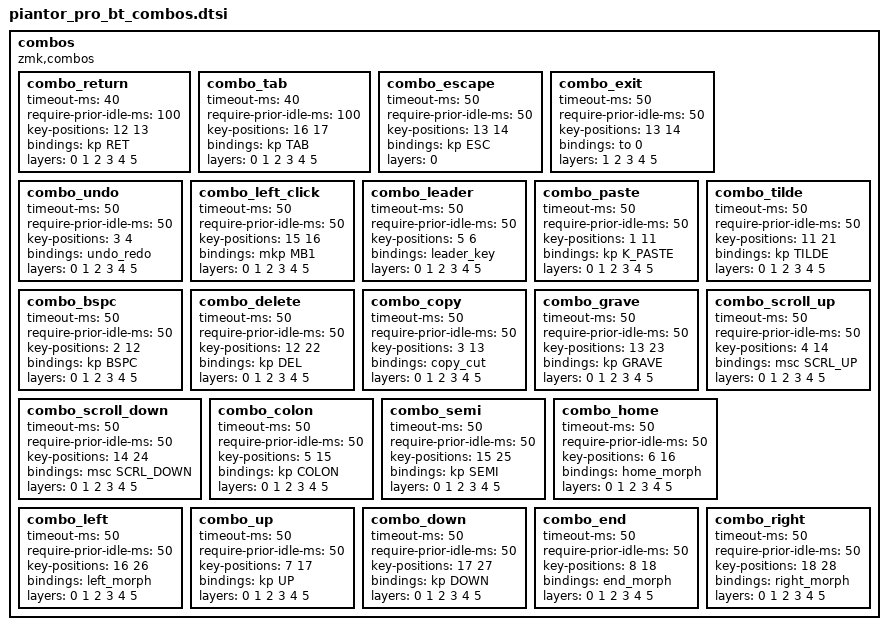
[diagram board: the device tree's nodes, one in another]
combos {
    compatible = "zmk,combos";

    // ===== CROSS-FINGER HORIZONTAL (40ms timeout, 100ms require-prior-idle) =====
    // Two different fingers on the same row: typing rolls can reach these, so the
    // window is tight and the prior-idle guard is long.
    combo_return {
        timeout-ms = <40>;
        require-prior-idle-ms = <100>;
        key-positions = <12 13>;  // T+S → Return
        bindings = <&kp RET>;
        layers = <0 1 2 3 4 5>;
    };
    combo_tab {
        timeout-ms = <40>;
        require-prior-idle-ms = <100>;
        key-positions = <16 17>;  // H+A → Tab
        bindings = <&kp TAB>;
        layers = <0 1 2 3 4 5>;
    };

    // ===== SINGLE-FINGER HORIZONTAL (50ms timeout, 50ms require-prior-idle) =====
    // Both index columns, worked by one finger. No roll risk.
    combo_escape {
        timeout-ms = <50>;
        require-prior-idle-ms = <50>;
        key-positions = <13 14>;  // S+G → Esc
        bindings = <&kp ESC>;
        layers = <0>;
    };
    combo_exit {
        timeout-ms = <50>;
        require-prior-idle-ms = <50>;
        key-positions = <13 14>;  // S+G → Exit to default layer
        bindings = <&to 0>;
        layers = <1 2 3 4 5>;
    };
    combo_undo {
        timeout-ms = <50>;
        require-prior-idle-ms = <50>;
        key-positions = <3 4>;  // C+V → Undo
        bindings = <&undo_redo>;
        layers = <0 1 2 3 4 5>;
    };
    combo_left_click {
        timeout-ms = <50>;
        require-prior-idle-ms = <50>;
        key-positions = <15 16>;  // Y+H → Left Click
        bindings = <&mkp MB1>;
        layers = <0 1 2 3 4 5>;
    };
    combo_leader {
        timeout-ms = <50>;
        require-prior-idle-ms = <50>;
        key-positions = <5 6>;  // Z+F → Leader
        bindings = <&leader_key>;
        layers = <0 1 2 3 4 5>;
    };

    // ===== VERTICAL COMBOS (50ms timeout, 50ms require-prior-idle) =====
    // Same column, adjacent rows. One finger presses both, and no bigram maps to a
    // same-column pair.

    // Column 1 (left ring) — paste and tilde
    combo_paste {
        timeout-ms = <50>;
        require-prior-idle-ms = <50>;
        key-positions = <1 11>;  // L+R → Paste
        bindings = <&kp K_PASTE>;
        layers = <0 1 2 3 4 5>;
    };
    combo_tilde {
        timeout-ms = <50>;
        require-prior-idle-ms = <50>;
        key-positions = <11 21>;  // R+Q → ~
        bindings = <&kp TILDE>;
        layers = <0 1 2 3 4 5>;
    };

    // Column 2 (left middle) — erase
    combo_bspc {
        timeout-ms = <50>;
        require-prior-idle-ms = <50>;
        key-positions = <2 12>;  // D+T → BSPC
        bindings = <&kp BSPC>;
        layers = <0 1 2 3 4 5>;
    };
    combo_delete {
        timeout-ms = <50>;
        require-prior-idle-ms = <50>;
        key-positions = <12 22>;  // T+M → Delete
        bindings = <&kp DEL>;
        layers = <0 1 2 3 4 5>;
    };

    // Column 3 (left index) — copy and grave
    combo_copy {
        timeout-ms = <50>;
        require-prior-idle-ms = <50>;
        key-positions = <3 13>;  // C+S → Copy (Shift = Cut)
        bindings = <&copy_cut>;
        layers = <0 1 2 3 4 5>;
    };
    combo_grave {
        timeout-ms = <50>;
        require-prior-idle-ms = <50>;
        key-positions = <13 23>;  // S+W → `
        bindings = <&kp GRAVE>;
        layers = <0 1 2 3 4 5>;
    };

    // Column 4 (left index stretch) — scroll
    combo_scroll_up {
        timeout-ms = <50>;
        require-prior-idle-ms = <50>;
        key-positions = <4 14>;  // V+G → Scroll Up
        bindings = <&msc SCRL_UP>;
        layers = <0 1 2 3 4 5>;
    };
    combo_scroll_down {
        timeout-ms = <50>;
        require-prior-idle-ms = <50>;
        key-positions = <14 24>;  // G+J → Scroll Down
        bindings = <&msc SCRL_DOWN>;
        layers = <0 1 2 3 4 5>;
    };

    // Column 5 (right index stretch) — symbols
    combo_colon {
        timeout-ms = <50>;
        require-prior-idle-ms = <50>;
        key-positions = <5 15>;  // Z+Y → :
        bindings = <&kp COLON>;
        layers = <0 1 2 3 4 5>;
    };
    combo_semi {
        timeout-ms = <50>;
        require-prior-idle-ms = <50>;
        key-positions = <15 25>;  // Y+K → ;
        bindings = <&kp SEMI>;
        layers = <0 1 2 3 4 5>;
    };

    // Columns 6-9 (right hand) — navigation
    combo_home {
        timeout-ms = <50>;
        require-prior-idle-ms = <50>;
        key-positions = <6 16>;  // F+H → Home
        bindings = <&home_morph>;
        layers = <0 1 2 3 4 5>;
    };
    combo_left {
        timeout-ms = <50>;
        require-prior-idle-ms = <50>;
        key-positions = <16 26>;  // H+P → Left
        bindings = <&left_morph>;
        layers = <0 1 2 3 4 5>;
    };
    combo_up {
        timeout-ms = <50>;
        require-prior-idle-ms = <50>;
        key-positions = <7 17>;  // O+A → Up
        bindings = <&kp UP>;
        layers = <0 1 2 3 4 5>;
    };
    combo_down {
        timeout-ms = <50>;
        require-prior-idle-ms = <50>;
        key-positions = <17 27>;  // A+, → Down
        bindings = <&kp DOWN>;
        layers = <0 1 2 3 4 5>;
    };
    combo_end {
        timeout-ms = <50>;
        require-prior-idle-ms = <50>;
        key-positions = <8 18>;  // U+E → End
        bindings = <&end_morph>;
        layers = <0 1 2 3 4 5>;
    };
    combo_right {
        timeout-ms = <50>;
        require-prior-idle-ms = <50>;
        key-positions = <18 28>;  // E+' → Right
        bindings = <&right_morph>;
        layers = <0 1 2 3 4 5>;
    };
};
